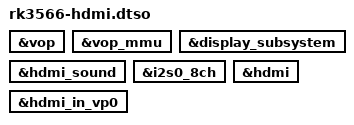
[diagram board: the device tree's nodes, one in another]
// SPDX-License-Identifier: (GPL-2.0+ OR MIT)

/dts-v1/;
/plugin/;

&vop {
	status = "okay";
};
&vop_mmu {
	status = "okay";
};
&display_subsystem {
	status = "okay";
};
&hdmi_sound {
	status = "okay";
};
&i2s0_8ch {
	status = "okay";
};
&hdmi {
	status = "okay";
};
&hdmi_in_vp0 {
	status = "okay";
};
